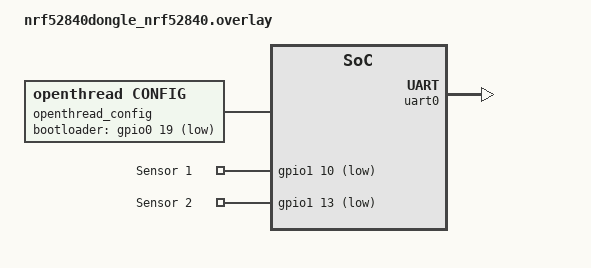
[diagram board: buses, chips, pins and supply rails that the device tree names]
/* Copyright (c) 2024 Nordic Semiconductor ASA
 *
 * SPDX-License-Identifier: LicenseRef-Nordic-5-Clause
 */

&uart0 {
    status = "okay";
    hw-flow-control;
};
&gpiote {
    status = "okay";
};

&led1_red {
    status = "disabled";
};

&led1_green {
    status = "disabled";
};

&led1_blue {
    status = "disabled";
};

&pwm0 {
    status = "disabled";
};
&i2c0 {
    status = "disabled";
};

&spi1 {
    status = "disabled";
};
/ {
    openthread_config: openthread {
        compatible = "openthread,config";
        bootloader-gpios = <&gpio0 19 GPIO_ACTIVE_LOW>;
    };

    aliases {
        sw0 = &sensor0;
        sw1 = &sensor1;
    };

    buttons {
    compatible = "gpio-keys";
    sensor0: sensor_0 {
    gpios = <&gpio1 10 GPIO_ACTIVE_LOW>;
    label = "Sensor 1";
};
sensor1: sensor_1 {
    gpios = <&gpio1 13 GPIO_ACTIVE_LOW>;
    label = "Sensor 2";
};
    };

};
